# ATtiny261A device description
Architecture: AVR8; Family: tinyAVR
Programming and debug interfaces: ISP, HVPP, debugWIRE
Registers are 8-bit, access not given, no defined reset value unless marked. A register's access mark holds for its fields unless they carry their own. Offsets are from the block's base; lines under a group give offsets from that group; [hi:lo] are bit positions; {n}, {i} and the like mark numbered series; 'fields as' and 'values as' point back to an identical list; <NAME> marks a mode.

## Ordering variants
ATtiny261A-MU, ATtiny261A-MUR: MLF32, up to 20 MHz, -40 to 85 C, 1.8 to 5.5 V
ATtiny261A-PU: PDIP20, up to 20 MHz, -40 to 85 C, 1.8 to 5.5 V
ATtiny261A-SU, ATtiny261A-SUR: SOIC20, up to 20 MHz, -40 to 85 C, 1.8 to 5.5 V
ATtiny261A-XU, ATtiny261A-XUR: TSSOP20, up to 20 MHz, -40 to 85 C, 1.8 to 5.5 V
ATtiny261A-MN, ATtiny261A-MNR: MLF32, up to 20 MHz, -40 to 105 C, 1.8 to 5.5 V

## Memory
prog space: start 0x0000 size 0x0800, little endian
  0x0000 FLASH size 0x0800 flash, rw, executable, page 0x20
signatures space: start 0 size 3, little endian
  0 SIGNATURES size 3 signatures, ro
fuses space: start 0 size 0x0003, little endian
  0 FUSES size 0x0003 fuses, rw
lockbits space: start 0 size 0x0001, little endian
  0 LOCKBITS size 0x0001 lockbits, rw
data space: start 0x0000 size 0x00e0, little endian
  0x0000 REGISTERS size 0x0020 regs
  0x0020 MAPPED_IO size 0x0040 io
  0x0060 IRAM size 0x0080 ram
eeprom space: start 0x0000 size 0x0080, little endian
  0x0000 EEPROM size 0x0080 eeprom, rw, page 0x04
io space: start 0x00 size 0x40, little endian
osccal space: start 0 size 1, little endian
  0 OSCCAL size 1 osccal, ro

## Peripheral instances (address, pins/pin function, parameters)
PORTA at 0x00 — I/O Port
PORTB at 0x00 — I/O Port
ADC at 0x00 — Analog-to-Digital Converter
AC at 0x00 — Analog Comparator
USI at 0x00 — Universal Serial Interface
EEPROM at 0x00
WDT at 0x00 — Watchdog Timer
TC0 at 0x00 — Timer/Counter, 8-bit
TC1 at 0x00 — Timer/Counter, 8-bit
BOOT_LOAD at 0x00 — Bootloader
EXINT at 0x00 — External Interrupts
CPU at 0x00 — CPU Registers
  parameters: CORE_VERSION=V2, NEW_INSTRUCTIONS=lpm rd,z+
FUSE at 0 in fuses — Fuses
LOCKBIT at 0 in lockbits — Lockbits

## Interrupts
0 RESET — External Reset, Power-on Reset and Watchdog Reset
1 INT0 — External Interrupt 0
2 PCINT — Pin Change Interrupt
3 TIMER1_COMPA — Timer/Counter1 Compare Match 1A
4 TIMER1_COMPB — Timer/Counter1 Compare Match 1B
5 TIMER1_OVF — Timer/Counter1 Overflow
6 TIMER0_OVF — Timer/Counter0 Overflow
7 USI_START
8 USI_OVF — USI Overflow
9 EE_RDY — EEPROM Ready
10 ANA_COMP — Analog Comparator
11 ADC — ADC Conversion Complete
12 WDT — Watchdog Time-Out
13 INT1 — External Interrupt 1
14 TIMER0_COMPA — Timer/Counter0 Compare Match A
15 TIMER0_COMPB — Timer/Counter0 Compare Match B
16 TIMER0_CAPT — ADC Conversion Complete
17 TIMER1_COMPD — Timer/Counter1 Compare Match D
18 FAULT_PROTECTION — Timer/Counter1 Fault Protection

## Properties
SIGNATURES: JTAGID=0x910C, SIGNATURE0=0x1e, SIGNATURE1=0x91, SIGNATURE2=0x0c
OCD: OCD_REVISION=1, OCD_DATAREG=0x20, PROGBASE=0x0000

## LOCKBIT — Lockbits
Instances: LOCKBIT 0 in lockbits
0x00 LOCKBIT reset 0xFF
  [1:0] LB — Memory Lock
    0=PROG_VER_DISABLED (Further programming and verification disabled); 2=PROG_DISABLED (Further programming disabled); 3=NO_LOCK (No memory lock features enabled)

## PORTA — I/O Port
Instances: PORTA 0x00
0x39 PINA — Port A Input Pins
0x3A DDRA — Port A Data Direction Register
0x3B PORTA — Port A Data Register

## PORTB — I/O Port
Instances: PORTB 0x00
0x36 PINB — Port B Input Pins
0x37 DDRB — Port B Data Direction Register
0x38 PORTB — Port B Data Register

## ADC — Analog-to-Digital Converter
Instances: ADC 0x00
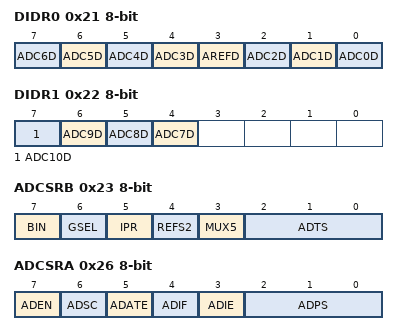
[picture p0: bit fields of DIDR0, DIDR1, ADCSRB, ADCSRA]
0x21 DIDR0 — Digital Input Disable Register 0
  [n+1] ADC{n}D (n=3..6) — ADC{n} Digital input Disable
  [3] AREFD — AREF Digital Input Disable
  [2] ADC2D — ADC2 Digital input Disable
  [1] ADC1D — ADC1 Digital input Disable
  [0] ADC0D — ADC0 Digital input Disable
0x22 DIDR1 — Digital Input Disable Register 1
  [n-3] ADC{n}D (n=7..10) — ADC{n} Digital input Disable
0x23 ADCSRB — ADC Control and Status Register B
  [7] BIN — Bipolar Input Mode
  [6] GSEL — Gain Select
  [5] IPR — Input Polarity Mode
  [4] REFS2
  [3] MUX5
  [2:0] ADTS — ADC Auto Trigger Sources
    0=FREE_RUNNING_MODE; 1=ANALOG_COMPARATOR; 2=EXTERNAL_INTERRUPT_REQUEST_0; 3=TIMER_COUNTER0_COMPARE_MATCH_A; 4=TIMER_COUNTER0_OVERFLOW; 5=TIMER_COUNTER1_COMPARE_MATCH_B; 6=TIMER_COUNTER1_OVERFLOW; 7=WATCHDOG_INTERRUPT_REQUEST
0x24 ADC 16-bit — ADC Data Register Bytes
0x26 ADCSRA — The ADC Control and Status register
  [7] ADEN — ADC Enable
  [6] ADSC — ADC Start Conversion
  [5] ADATE — ADC Auto Trigger Enable
  [4] ADIF — ADC Interrupt Flag
  [3] ADIE — ADC Interrupt Enable
  [2:0] ADPS — ADC Prescaler Select Bits
    0=2; 1=2; 2=4; 3=8; 4=16; 5=32; 6=64; 7=128
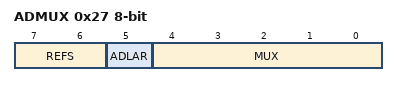
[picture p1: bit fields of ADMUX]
0x27 ADMUX — The ADC multiplexer Selection Register
  [7:6] REFS — Reference Selection Bits
  [5] ADLAR — Left Adjust Result
  [4:0] MUX — Analog Channel and Gain Selection Bits
